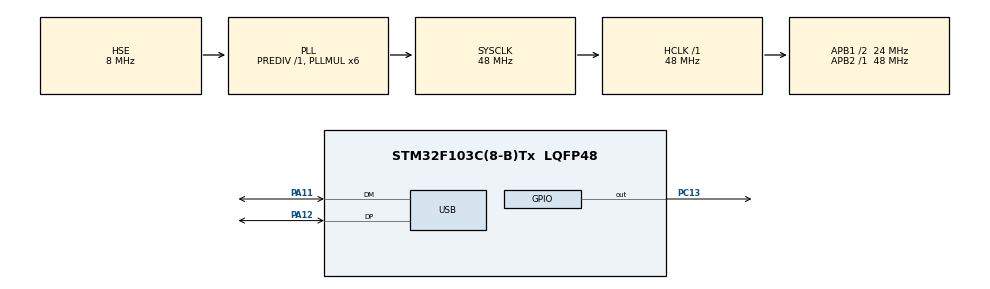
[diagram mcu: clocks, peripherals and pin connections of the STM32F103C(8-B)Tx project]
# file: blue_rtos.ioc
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FREERTOS.Tasks01=blink01,24,128,StartBlink01,Default,NULL,Dynamic,NULL,NULL;blink02,16,128,StartBlink02,Default,NULL,Dynamic,NULL,NULL
Mcu.Family=STM32F1
Mcu.Name=STM32F103C(8-B)Tx
Mcu.Package=LQFP48
NVIC.PriorityGroup=NVIC_PRIORITYGROUP_4
NVIC.TIM4_IRQn=true\:0\:0\:false\:false\:true\:false\:false\:true
NVIC.TimeBase=TIM4_IRQn
NVIC.TimeBaseIP=TIM4
NVIC.USB_LP_CAN1_RX0_IRQn=true\:5\:0\:false\:false\:true\:true\:false\:true
PA11.Mode=Device
PA11.Signal=USB_DM
PA12.Mode=Device
PA12.Signal=USB_DP
PA13.Mode=Serial_Wire
PA13.Signal=SYS_JTMS-SWDIO
PA14.Mode=Serial_Wire
PA14.Signal=SYS_JTCK-SWCLK
PC13-TAMPER-RTC.Signal=GPIO_Output
PD0-OSC_IN.Mode=HSE-External-Oscillator
PD0-OSC_IN.Signal=RCC_OSC_IN
PD1-OSC_OUT.Mode=HSE-External-Oscillator
PD1-OSC_OUT.Signal=RCC_OSC_OUT
ProjectManager.HeapSize=0x200
ProjectManager.StackSize=0x400
ProjectManager.TargetToolchain=STM32CubeIDE
RCC.AHBFreq_Value=48000000
RCC.APB1CLKDivider=RCC_HCLK_DIV2
RCC.APB1Freq_Value=24000000
RCC.APB1TimFreq_Value=48000000
RCC.APB2Freq_Value=48000000
RCC.APB2TimFreq_Value=48000000
RCC.HCLKFreq_Value=48000000
RCC.PLLMUL=RCC_PLL_MUL6
RCC.PLLSourceVirtual=RCC_PLLSOURCE_HSE
RCC.SYSCLKFreq_VALUE=48000000
RCC.SYSCLKSource=RCC_SYSCLKSOURCE_PLLCLK
RCC.USBFreq_Value=48000000
TIM3.AutoReloadPreload=TIM_AUTORELOAD_PRELOAD_ENABLE
TIM3.Prescaler=72
USB_DEVICE.CLASS_NAME_FS=CDC
USB_DEVICE.VirtualMode=Cdc
USB_DEVICE.VirtualModeFS=Cdc_FS
VP_FREERTOS_VS_CMSIS_V2.Mode=CMSIS_V2
VP_SYS_VS_tim4.Mode=TIM4
VP_TIM3_VS_ClockSourceINT.Mode=Internal
VP_USB_DEVICE_VS_USB_DEVICE_CDC_FS.Mode=CDC_FS
board=custom

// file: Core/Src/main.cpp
/* USER CODE BEGIN Header */
/*
 * Location : C:\Users\aronno\STM32CubeIDE\workspace_1.1.0\blue_rtos
 * Uploaded to https://github.com/jibonaronno/blue_rtos
 *
 * C++ implemented.
 * Added delay.cpp -> void delay_us (uint32_t us, TIM_HandleTypeDef *htim)
 * The timer is htim3 or Timer3, preconfigured from cube mx.
 * Prescaler is 72
 * Period is 65535
 * Auto Reload Preload : Enabled
*/
/* USER CODE END Header */
#include "main.h"
#include "cmsis_os.h"
#include "usb_device.h"

/* USER CODE BEGIN Includes */
#include "usbd_cdc_if.h"
#include "delay.h"

/* USER CODE END Includes */

TIM_HandleTypeDef htim3;

/* Definitions for blink01 */
osThreadId_t blink01Handle;
osThreadAttr_t blink01_attributes;
/* Definitions for blink02 */
osThreadId_t blink02Handle;
osThreadAttr_t blink02_attributes;

void SystemClock_Config(void);
static void MX_GPIO_Init(void);
static void MX_TIM3_Init(void);
void StartBlink01(void *argument);
void StartBlink02(void *argument);

int main(void)
{

  /* MCU Configuration--------------------------------------------------------*/

  /* Reset of all peripherals, Initializes the Flash interface and the Systick. */
  HAL_Init();

  /* Configure the system clock */
  SystemClock_Config();

  /* Initialize all configured peripherals */
  MX_GPIO_Init();
  MX_TIM3_Init();
  /* USER CODE BEGIN 2 */

  blink01_attributes.name = "blink01";
  blink01_attributes.stack_size = 128 * 4;
  blink01_attributes.priority = (osPriority_t) osPriorityNormal;

  blink02_attributes.name = "blink02";
  blink02_attributes.priority = (osPriority_t) osPriorityBelowNormal;
  blink02_attributes.stack_size = 128 * 4;

  /* USER CODE END 2 */

  /* Init scheduler */
  osKernelInitialize();

  /* Create the thread(s) */
  /* creation of blink01 */
  blink01Handle = osThreadNew(StartBlink01, NULL, &blink01_attributes);

  /* creation of blink02 */
  blink02Handle = osThreadNew(StartBlink02, NULL, &blink02_attributes);

  /* USER CODE BEGIN RTOS_THREADS */

  HAL_TIM_Base_Start(&htim3);

  /* add threads, ... */
  /* USER CODE END RTOS_THREADS */

  /* Start scheduler */
  osKernelStart();

  /* We should never get here as control is now taken by the scheduler */
  /* Infinite loop */
  while (1)
  {

  }
}

void SystemClock_Config(void)
{
  RCC_OscInitTypeDef RCC_OscInitStruct = {0};
  RCC_ClkInitTypeDef RCC_ClkInitStruct = {0};
  RCC_PeriphCLKInitTypeDef PeriphClkInit = {0};

  /** Initializes the RCC Oscillators according to the specified parameters
  * in the RCC_OscInitTypeDef structure.
  */
  RCC_OscInitStruct.OscillatorType = RCC_OSCILLATORTYPE_HSE;
  RCC_OscInitStruct.HSEState = RCC_HSE_ON;
  RCC_OscInitStruct.HSEPredivValue = RCC_HSE_PREDIV_DIV1;
  RCC_OscInitStruct.HSIState = RCC_HSI_ON;
  RCC_OscInitStruct.PLL.PLLState = RCC_PLL_ON;
  RCC_OscInitStruct.PLL.PLLSource = RCC_PLLSOURCE_HSE;
  RCC_OscInitStruct.PLL.PLLMUL = RCC_PLL_MUL6;
  if (HAL_RCC_OscConfig(&RCC_OscInitStruct) != HAL_OK)
  {
    Error_Handler();
  }
  /** Initializes the CPU, AHB and APB buses clocks
  */
  RCC_ClkInitStruct.ClockType = RCC_CLOCKTYPE_HCLK|RCC_CLOCKTYPE_SYSCLK
                              |RCC_CLOCKTYPE_PCLK1|RCC_CLOCKTYPE_PCLK2;
  RCC_ClkInitStruct.SYSCLKSource = RCC_SYSCLKSOURCE_PLLCLK;
  RCC_ClkInitStruct.AHBCLKDivider = RCC_SYSCLK_DIV1;
  RCC_ClkInitStruct.APB1CLKDivider = RCC_HCLK_DIV2;
  RCC_ClkInitStruct.APB2CLKDivider = RCC_HCLK_DIV1;

  if (HAL_RCC_ClockConfig(&RCC_ClkInitStruct, FLASH_LATENCY_1) != HAL_OK)
  {
    Error_Handler();
  }
  PeriphClkInit.PeriphClockSelection = RCC_PERIPHCLK_USB;
  PeriphClkInit.UsbClockSelection = RCC_USBCLKSOURCE_PLL;
  if (HAL_RCCEx_PeriphCLKConfig(&PeriphClkInit) != HAL_OK)
  {
    Error_Handler();
  }
}

static void MX_TIM3_Init(void)
{

  TIM_ClockConfigTypeDef sClockSourceConfig = {0};
  TIM_MasterConfigTypeDef sMasterConfig = {0};

  htim3.Instance = TIM3;
  htim3.Init.Prescaler = 72;
  htim3.Init.CounterMode = TIM_COUNTERMODE_UP;
  htim3.Init.Period = 65535;
  htim3.Init.ClockDivision = TIM_CLOCKDIVISION_DIV1;
  htim3.Init.AutoReloadPreload = TIM_AUTORELOAD_PRELOAD_ENABLE;
  if (HAL_TIM_Base_Init(&htim3) != HAL_OK)
  {
    Error_Handler();
  }
  sClockSourceConfig.ClockSource = TIM_CLOCKSOURCE_INTERNAL;
  if (HAL_TIM_ConfigClockSource(&htim3, &sClockSourceConfig) != HAL_OK)
  {
    Error_Handler();
  }
  sMasterConfig.MasterOutputTrigger = TIM_TRGO_RESET;
  sMasterConfig.MasterSlaveMode = TIM_MASTERSLAVEMODE_DISABLE;
  if (HAL_TIMEx_MasterConfigSynchronization(&htim3, &sMasterConfig) != HAL_OK)
  {
    Error_Handler();
  }

}

static void MX_GPIO_Init(void)
{
  GPIO_InitTypeDef GPIO_InitStruct = {0};

  /* GPIO Ports Clock Enable */
  __HAL_RCC_GPIOC_CLK_ENABLE();
  __HAL_RCC_GPIOD_CLK_ENABLE();
  __HAL_RCC_GPIOA_CLK_ENABLE();

  /*Configure GPIO pin Output Level */
  HAL_GPIO_WritePin(GPIOC, GPIO_PIN_13, GPIO_PIN_RESET);

  /*Configure GPIO pin : PC13 */
  GPIO_InitStruct.Pin = GPIO_PIN_13;
  GPIO_InitStruct.Mode = GPIO_MODE_OUTPUT_PP;
  GPIO_InitStruct.Pull = GPIO_NOPULL;
  GPIO_InitStruct.Speed = GPIO_SPEED_FREQ_LOW;
  HAL_GPIO_Init(GPIOC, &GPIO_InitStruct);

}

void StartBlink01(void *argument)
{
  /* init code for USB_DEVICE */
  MX_USB_DEVICE_Init();
  /* USER CODE BEGIN 5 */
	uint8_t flagToggle = 0;
	uint16_t lCounter01 = 0;
  /* Infinite loop */
  for(;;)
  {
	//From Reference file:///C:/drive.google/ARM/DOCS.drop/PRIMARY/ARM-CMSIS-6.html signal is used, but from
	//Version2 signal is replaced with flags.
	//osSignalWait(0x01, osWaitForever);
	osThreadFlagsWait(0x00000001U, osFlagsWaitAny, osWaitForever); // Wait forever until thread flag 1 is set.
    //osDelay(500);
    if(flagToggle==0)
    {
    	HAL_GPIO_WritePin(GPIOC, GPIO_PIN_13, GPIO_PIN_SET);
    	for(lCounter01=0;lCounter01<10;lCounter01++)
    	{
    		delay_us(10000, &htim3);
    		delay_us(10000, &htim3);
    		delay_us(10000, &htim3);
    		delay_us(10000, &htim3);
    		HAL_GPIO_TogglePin(GPIOC, GPIO_PIN_13);
    	}
    	flagToggle = 1;
    	lCounter01 = 0;
    }
    else
    {
    	HAL_GPIO_WritePin(GPIOC, GPIO_PIN_13, GPIO_PIN_RESET);
    	flagToggle = 0;
    }

  }

  /* USER CODE END 5 */
}

void StartBlink02(void *argument)
{
  /* USER CODE BEGIN StartBlink02 */
  /* Infinite loop */
  for(;;)
  {
    osDelay(400);
    osThreadFlagsSet(blink01Handle, 0x00000001U);
  }
  /* USER CODE END StartBlink02 */
}

 /**
  * @brief  Period elapsed callback in non blocking mode
  * @note   This function is called  when TIM4 interrupt took place, inside
  * HAL_TIM_IRQHandler(). It makes a direct call to HAL_IncTick() to increment
  * a global variable "uwTick" used as application time base.
  * @param  htim : TIM handle
  * @retval None
  */
void HAL_TIM_PeriodElapsedCallback(TIM_HandleTypeDef *htim)
{
  if (htim->Instance == TIM4) {
    HAL_IncTick();
  }
}

void Error_Handler(void)
{
  __disable_irq();
  while (1)
  {
  }
}

/************************ (C) COPYRIGHT STMicroelectronics *****END OF FILE****/
